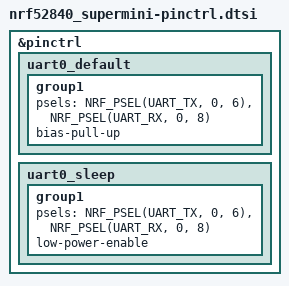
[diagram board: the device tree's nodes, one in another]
/* SPDX-License-Identifier: Apache-2.0 */

&pinctrl {
    uart0_default: uart0_default {
        group1 {
            psels = <NRF_PSEL(UART_TX, 0, 6)>,
                     <NRF_PSEL(UART_RX, 0, 8)>;
            bias-pull-up;
        };
    };

    uart0_sleep: uart0_sleep {
        group1 {
            psels = <NRF_PSEL(UART_TX, 0, 6)>,
                     <NRF_PSEL(UART_RX, 0, 8)>;
            low-power-enable;
        };
    };
};
